# STM32WBA52 register map
File version: 0.1
CPU: CM33 r0p1, little endian, MPU, FPU, 4 interrupt priority bits
Registers are 32-bit, read-write, reset 0x0 unless marked. A register's access mark holds for its fields unless they carry their own. Offsets are from the block's base; [hi:lo] are bit positions; {n}, {i} and the like mark numbered series; 'fields as' and 'values as' point back to an identical list.

## HASH — Hash processor
Base 0x420C0400
Same registers: SEC_HASH 0x520C0400
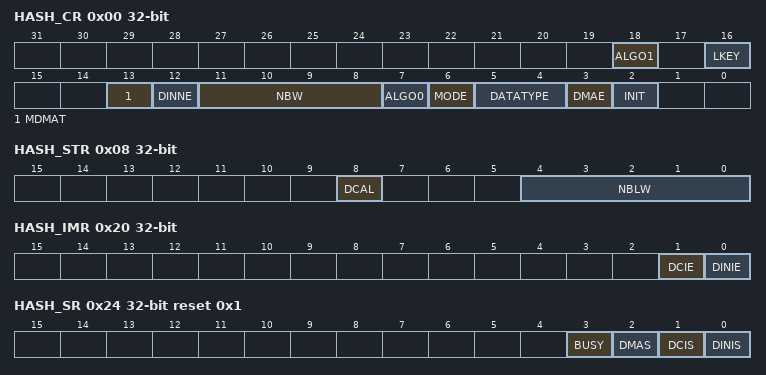
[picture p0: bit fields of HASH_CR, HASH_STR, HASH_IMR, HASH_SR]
0x00 HASH_CR access per field — HASH control register
  [18] ALGO1 rw — Algorithm selection These bits select the hash algorithm. This selection is only taken into account when the INIT bit is set. Changing this bitfield during a computation has no effect.
    0=SHA-1; 1=MD5; 2=SHA-224; 3=SHA-256
  [16] LKEY rw — Long key selection This bit selects between short key (≤ 64 bytes) or long key (> 64 bytes) in HMAC mode. This selection is only taken into account when the INIT bit is set and MODE = 1. Changing this bit during a computation has no effect.
    0=the HMAC key is shorter or equal to 64 bytes. The actual key value written to HASH_DIN is used during the HMAC computation.; 1=the HMAC key is longer than 64 bytes. The hash of the key is used instead of the real key during the HMAC computation.
  [13] MDMAT rw — Multiple DMA transfers This bit is set when hashing large files when multiple DMA transfers are needed.
    0=DCAL is automatically set at the end of a DMA transfer; 1=DCAL is not automatically set at the end of a DMA transfer
  [12] DINNE ro — DIN not empty This bit is set when the HASH_DIN register holds valid data (that is after being written at least once). It is cleared when either the INIT bit (initialization) or the DCAL bit (completion of the previous message processing) is written to 1. This bit is read-only.
    0=No data are present in the data input buffer; 1=The input buffer contains at least one word of data
  [11:8] NBW ro — Number of words already pushed This bitfield reflects the number of words in the message that have already been pushed into the IN FIFO. NBW is incremented by one when a write access to the HASH_DIN register is performed (except if DINNE = 0 and the DMA is not used, see below description). NBW goes to zero when the INIT bit is written to 1. This bitfield is read-only. If the DMA is not used ... If the DMA is used NBW contains the exact number of words that have been pushed into the IN FIFO by the DMA.
    0=if DINNE = 0, no word has been pushed into the DIN buffer (both HASH_DIN register and IN FIFO are empty), otherwise one word has been pushed into the DIN buffer (HASH_DIN register contains one word and IN FIFO is empty); 1=two words have been pushed into the DIN buffer (that is HASH_DIN register and the IN FIFO contain one word each); 15=16 words have been pushed into the DIN buffer
  [7] ALGO0 rw — Algorithm selection These bits select the hash algorithm. This selection is only taken into account when the INIT bit is set. Changing this bitfield during a computation has no effect.
    0=SHA-1; 1=MD5; 2=SHA-224; 3=SHA-256
  [6] MODE rw — Mode selection This bit selects the HASH or HMAC mode for the selected algorithm: This selection is only taken into account when the INIT bit is set. Changing this bit during a computation has no effect.
    0=Hash mode selected; 1=HMAC mode selected. LKEY must be set if the key being used is longer than 64 bytes.
  [5:4] DATATYPE rw — Data type selection Defines the format of the data entered into the HASH_DIN register:
    0=32-bit data. The data written into HASH_DIN are directly used by the HASH processing, without reordering.; 1=16-bit data, or half-word. The data written into HASH_DIN are considered as two half-words, and are swapped before being used by the HASH processing.; 2=8-bit data, or bytes. The data written into HASH_DIN are considered as four bytes, and are swapped before being used by the HASH processing.; 3=bit data, or bit-string. The data written into HASH_DIN are considered as 32 bits (1st bit of the string at position 0), and are swapped before being used by the HASH processing (1st bit of the string at position 31).
  [3] DMAE rw — DMA enable After this bit is set it is cleared by hardware while the last data of the message is written into the hash processor. Setting this bit to 0 while a DMA transfer is ongoing is not aborting this current transfer. Instead, the DMA interface of the IP remains internally enabled until the transfer is completed or INIT is written to 1. Setting INIT bit to 1 does not clear DMAE bit.
    0=DMA transfers disabled; 1=DMA transfers enabled. A DMA request is sent as soon as the HASH core is ready to receive data.
  [2] INIT rw — Initialize message digest calculation Writing this bit to 1 resets the hash processor core, so that the HASH is ready to compute the message digest of a new message. Writing this bit to 0 has no effect. Reading this bit always return 0.
0x04 HASH_DIN — HASH data input register
  [31:0] DATAIN — Data input Writing this register pushes the current register content into the IN FIFO, and the register takes the new value presented on the AHB databus. Reading this register returns the current register content.
0x08 HASH_STR — HASH start register
  [8] DCAL — Digest calculation Writing this bit to 1 starts the message padding, using the previously written value of NBLW[4:0], and starts the calculation of the final message digest with all data words written to the input FIFO since the INIT bit was last written to 1. Reading this bit returns 0.
  [4:0] NBLW — Number of valid bits in the last word When the last word of the message bit string is written in HASH_DIN register, the hash processor takes only the valid bits specified as below, after internal data swapping: ... The above mechanism is valid only if DCAL = 0. If NBLW[4:0] bitfield is written while DCAL is set to 1, the NBLW[4:0] bitfield remains unchanged. In other words it is not possible to configure NBLW[4:0] and set DCAL at the same time. Reading NBLW[4:0] bitfield returns the last value written to NBLW[4:0].
    0=All 32 bits of the last data written are valid message bits that is M[31:0]; 1=Only one bit of the last data written (after swapping) is valid that is M[0]; 2=Only two bits of the last data written (after swapping) are valid that is M[1:0]; 3=Only three bits of the last data written (after swapping) are valid that is M[2:0]; 31=Only 31 bits of the last data written (after swapping) are valid that is M[30:0]
{0xC+4i} HASH_HRA{i} ro (i=0..4) — HASH aliased digest register {i}
  [31:0] H{i} — Hash data x Refer to Section 40.7.4: HASH digest registers introduction.
0x20 HASH_IMR — HASH interrupt enable register
  [1] DCIE — Digest calculation completion interrupt enable
    0=Digest calculation completion interrupt disabled; 1=Digest calculation completion interrupt enabled
  [0] DINIE — Data input interrupt enable
    0=Data input interrupt disabled; 1=Data input interrupt enabled
0x24 HASH_SR access per field reset 0x1 — HASH status register
  [3] BUSY ro — Busy bit
    0=No block is currently being processed; 1=The hash core is processing a block of data
  [2] DMAS ro — DMA Status This bit provides information on the DMA interface activity. It is set with DMAE and cleared when DMAE = 0 and no DMA transfer is ongoing. No interrupt is associated with this bit.
    0=DMA interface is disabled (DMAE = 0) and no transfer is ongoing; 1=DMA interface is enabled (DMAE = 1) or a transfer is ongoing
  [1] DCIS rw — Digest calculation completion interrupt status This bit is set by hardware when a digest becomes ready (the whole message has been processed). It is cleared by writing it to 0 or by writing the INIT bit to 1 in the HASH_CR register.
    0=No digest available in the HASH_HRx registers (zeros are returned); 1=Digest calculation complete, a digest is available in the HASH_HRx registers. An interrupt is generated if the DCIE bit is set in the HASH_IMR register.
  [0] DINIS rw — Data input interrupt status This bit is set by hardware when the FIFO is ready to get a new block (16 locations are free). It is cleared by writing it to 0 or by writing the HASH_DIN register. When DINIS=0, HASH_CSRx registers reads as zero.
    0=Less than 16 locations are free in the input buffer; 1=A new block can be entered into the input buffer. An interrupt is generated if the DINIE bit is set in the HASH_IMR register.
{0xF8+4i} HASH_CSR{i} (i=0..53) — HASH context swap register {i}
  [31:0] CS{i} — Context swap x Refer to Section 40.7.7: HASH context swap registers introduction.
{0x310+4i} HASH_HR{i} ro (i=0..4) — HASH digest register {i}
  fields as HASH_HRA0
{0x310+4i} HASH_HR{i} ro (i=5..7) — HASH supplementary digest register {i}
  fields as HASH_HRA0
